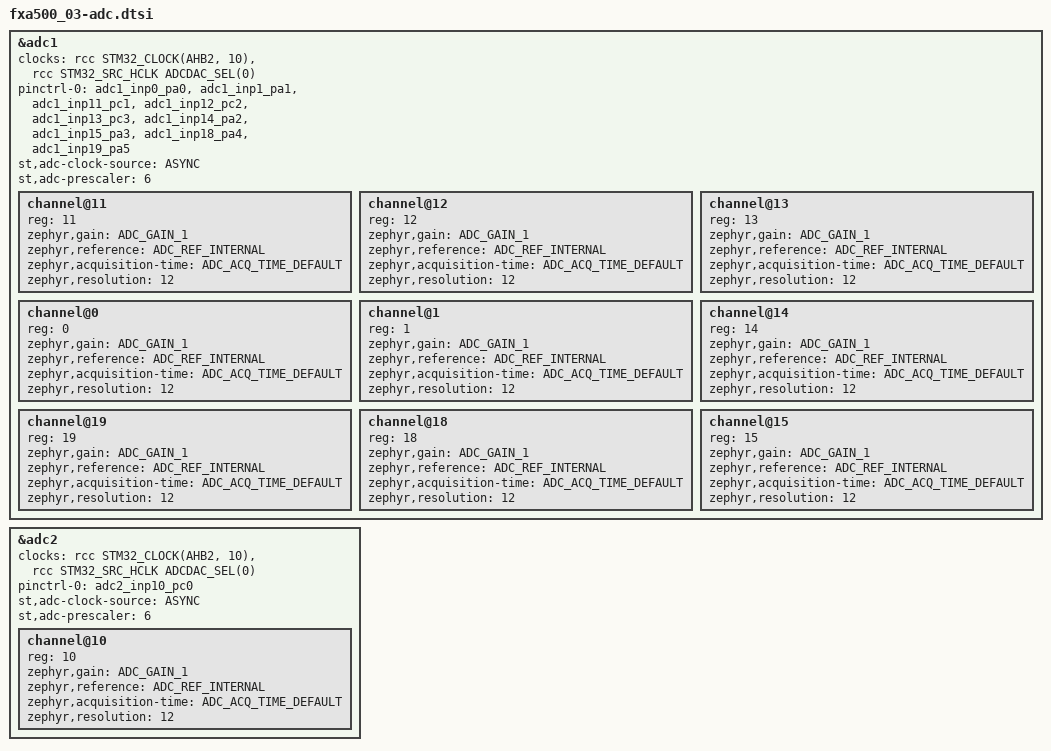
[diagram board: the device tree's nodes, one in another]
&adc1 {
	#address-cells = <1>;
	#size-cells = <0>;

	clocks = <&rcc STM32_CLOCK(AHB2, 10)>,
		 <&rcc STM32_SRC_HCLK ADCDAC_SEL(0)>;
	pinctrl-0 = <
		&adc1_inp0_pa0
		&adc1_inp1_pa1
		&adc1_inp11_pc1
		&adc1_inp12_pc2
		&adc1_inp13_pc3
		&adc1_inp14_pa2
		&adc1_inp15_pa3
		&adc1_inp18_pa4
		&adc1_inp19_pa5
	>;
	pinctrl-names = "default";
	clock-names = "adcx", "adc_ker";
	st,adc-clock-source = "ASYNC";
	st,adc-prescaler = <6>;
	status = "okay";

	channel@11 {
		reg = <11>;
		zephyr,gain = "ADC_GAIN_1";
		zephyr,reference = "ADC_REF_INTERNAL";
		zephyr,acquisition-time = <ADC_ACQ_TIME_DEFAULT>;
		zephyr,resolution = <12>;
	};

	channel@12 {
		reg = <12>;
		zephyr,gain = "ADC_GAIN_1";
		zephyr,reference = "ADC_REF_INTERNAL";
		zephyr,acquisition-time = <ADC_ACQ_TIME_DEFAULT>;
		zephyr,resolution = <12>;
	};

	channel@13 {
		reg = <13>;
		zephyr,gain = "ADC_GAIN_1";
		zephyr,reference = "ADC_REF_INTERNAL";
		zephyr,acquisition-time = <ADC_ACQ_TIME_DEFAULT>;
		zephyr,resolution = <12>;
	};

	channel@0 {
		reg = <0>;
		zephyr,gain = "ADC_GAIN_1";
		zephyr,reference = "ADC_REF_INTERNAL";
		zephyr,acquisition-time = <ADC_ACQ_TIME_DEFAULT>;
		zephyr,resolution = <12>;
	};

	channel@1 {
		reg = <1>;
		zephyr,gain = "ADC_GAIN_1";
		zephyr,reference = "ADC_REF_INTERNAL";
		zephyr,acquisition-time = <ADC_ACQ_TIME_DEFAULT>;
		zephyr,resolution = <12>;
	};

	channel@14 {
		reg = <14>;
		zephyr,gain = "ADC_GAIN_1";
		zephyr,reference = "ADC_REF_INTERNAL";
		zephyr,acquisition-time = <ADC_ACQ_TIME_DEFAULT>;
		zephyr,resolution = <12>;
	};

	channel@19 {
		reg = <19>;
		zephyr,gain = "ADC_GAIN_1";
		zephyr,reference = "ADC_REF_INTERNAL";
		zephyr,acquisition-time = <ADC_ACQ_TIME_DEFAULT>;
		zephyr,resolution = <12>;
	};

	channel@18 {
		reg = <18>;
		zephyr,gain = "ADC_GAIN_1";
		zephyr,reference = "ADC_REF_INTERNAL";
		zephyr,acquisition-time = <ADC_ACQ_TIME_DEFAULT>;
		zephyr,resolution = <12>;
	};

	channel@15 {
		reg = <15>;
		zephyr,gain = "ADC_GAIN_1";
		zephyr,reference = "ADC_REF_INTERNAL";
		zephyr,acquisition-time = <ADC_ACQ_TIME_DEFAULT>;
		zephyr,resolution = <12>;
	};


};

&adc2 {
	#address-cells = <1>;
	#size-cells = <0>;

	clocks = <&rcc STM32_CLOCK(AHB2, 10)>,
		 <&rcc STM32_SRC_HCLK ADCDAC_SEL(0)>;
	pinctrl-0 = <&adc2_inp10_pc0>;
	pinctrl-names = "default";
	clock-names = "adcx", "adc_ker";
	st,adc-clock-source = "ASYNC";
	st,adc-prescaler = <6>;
	status = "okay";

	channel@10 {
		reg = <10>;
		zephyr,gain = "ADC_GAIN_1";
		zephyr,reference = "ADC_REF_INTERNAL";
		zephyr,acquisition-time = <ADC_ACQ_TIME_DEFAULT>;
		zephyr,resolution = <12>;
	};

};
